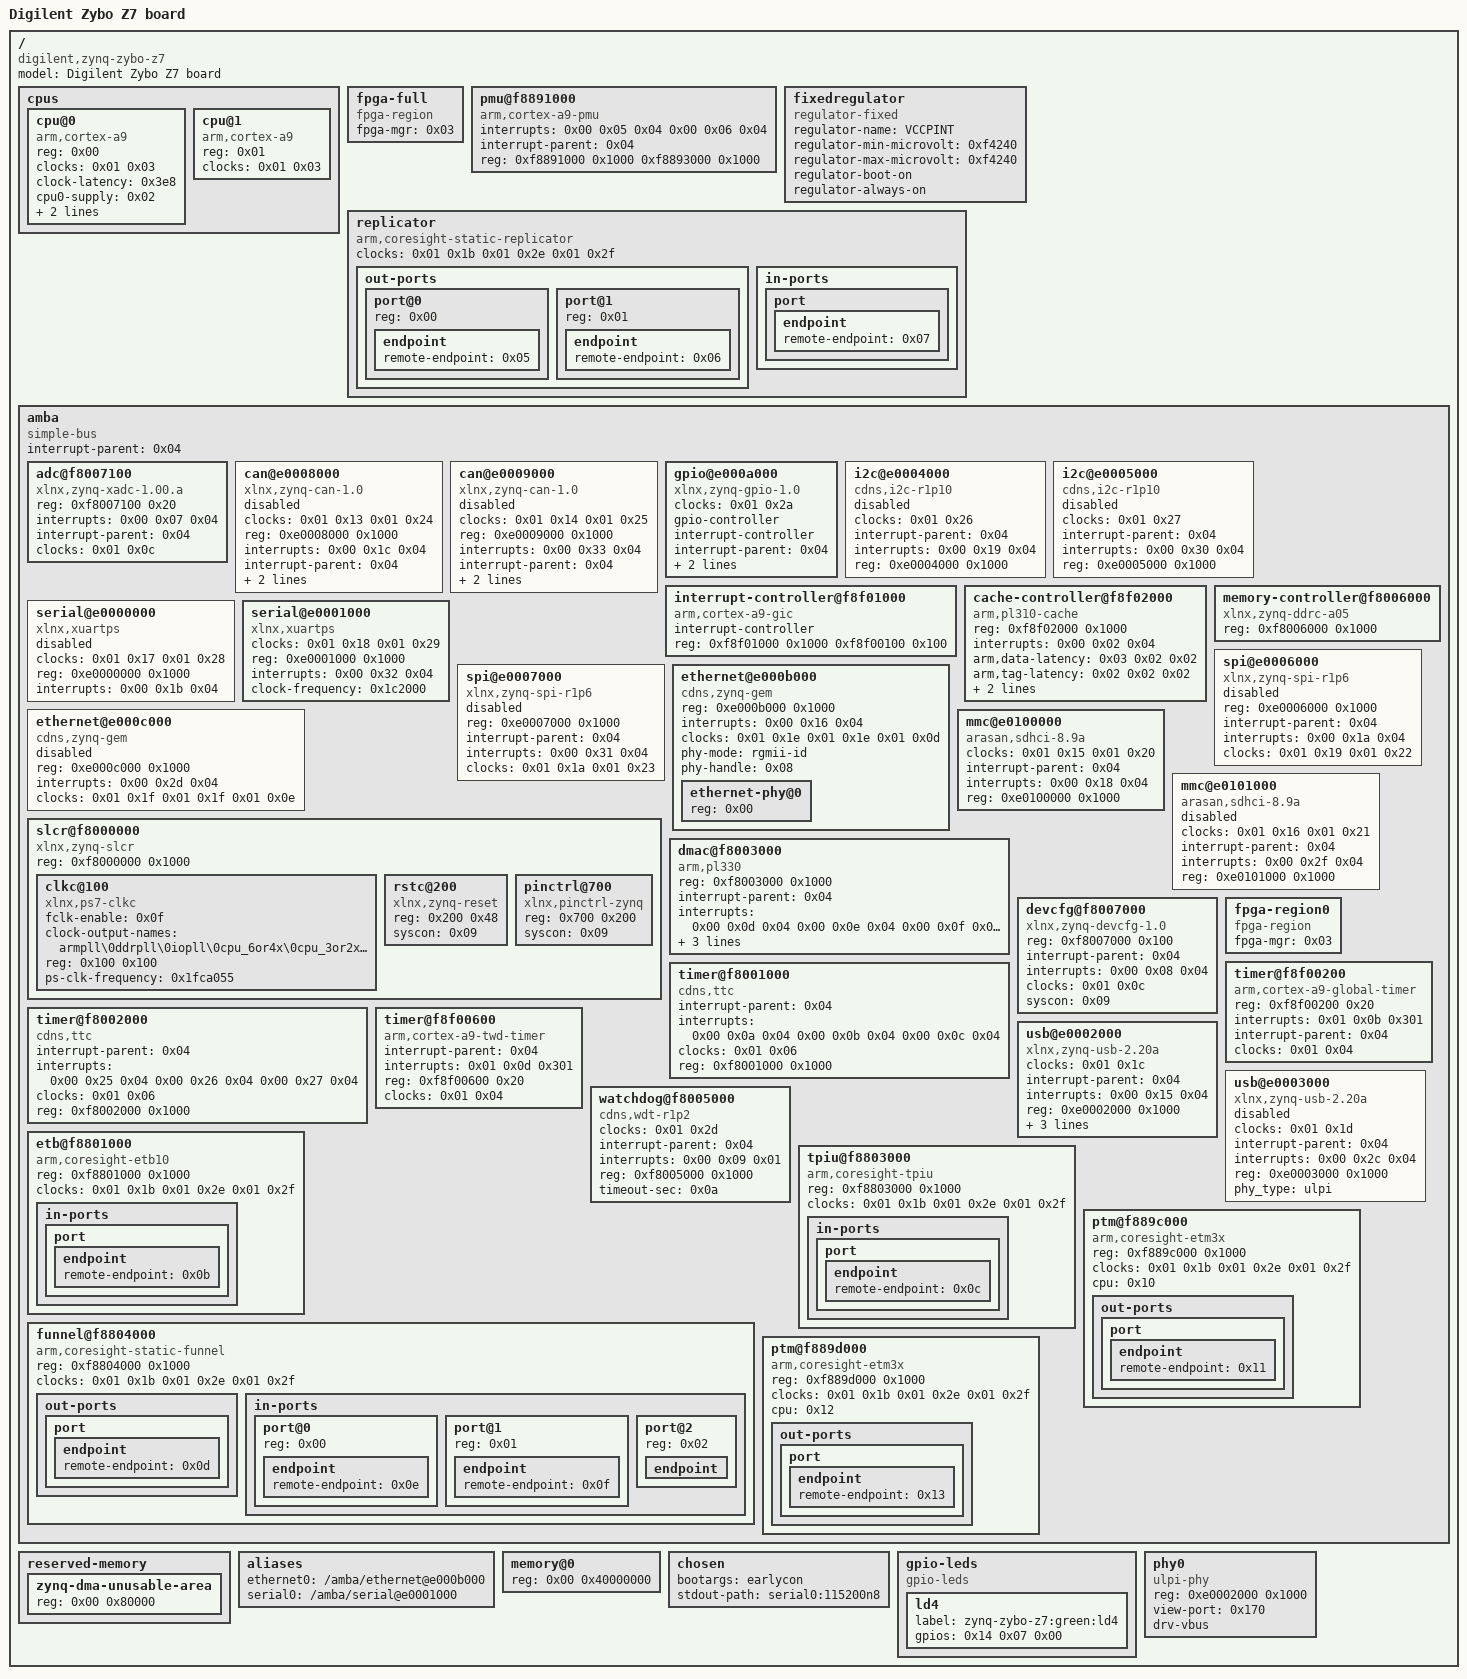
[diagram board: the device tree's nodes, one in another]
/dts-v1/;

/ {
	#address-cells = <0x01>;
	#size-cells = <0x01>;
	compatible = "digilent,zynq-zybo-z7\0xlnx,zynq-7000";
	model = "Digilent Zybo Z7 board";

	cpus {
		#address-cells = <0x01>;
		#size-cells = <0x00>;

		cpu@0 {
			compatible = "arm,cortex-a9";
			device_type = "cpu";
			reg = <0x00>;
			clocks = <0x01 0x03>;
			clock-latency = <0x3e8>;
			cpu0-supply = <0x02>;
			operating-points = <0xa2c2b 0xf4240 0x51616 0xf4240>;
			phandle = <0x10>;
		};

		cpu@1 {
			compatible = "arm,cortex-a9";
			device_type = "cpu";
			reg = <0x01>;
			clocks = <0x01 0x03>;
			phandle = <0x12>;
		};
	};

	fpga-full {
		compatible = "fpga-region";
		fpga-mgr = <0x03>;
		#address-cells = <0x01>;
		#size-cells = <0x01>;
		ranges;
		phandle = <0x15>;
	};

	pmu@f8891000 {
		compatible = "arm,cortex-a9-pmu";
		interrupts = <0x00 0x05 0x04 0x00 0x06 0x04>;
		interrupt-parent = <0x04>;
		reg = <0xf8891000 0x1000 0xf8893000 0x1000>;
	};

	fixedregulator {
		compatible = "regulator-fixed";
		regulator-name = "VCCPINT";
		regulator-min-microvolt = <0xf4240>;
		regulator-max-microvolt = <0xf4240>;
		regulator-boot-on;
		regulator-always-on;
		phandle = <0x02>;
	};

	replicator {
		compatible = "arm,coresight-static-replicator";
		clocks = <0x01 0x1b 0x01 0x2e 0x01 0x2f>;
		clock-names = "apb_pclk\0dbg_trc\0dbg_apb";

		out-ports {
			#address-cells = <0x01>;
			#size-cells = <0x00>;

			port@0 {
				reg = <0x00>;

				endpoint {
					remote-endpoint = <0x05>;
					phandle = <0x0c>;
				};
			};

			port@1 {
				reg = <0x01>;

				endpoint {
					remote-endpoint = <0x06>;
					phandle = <0x0b>;
				};
			};
		};

		in-ports {

			port {

				endpoint {
					remote-endpoint = <0x07>;
					phandle = <0x0d>;
				};
			};
		};
	};

	amba {
		compatible = "simple-bus";
		#address-cells = <0x01>;
		#size-cells = <0x01>;
		interrupt-parent = <0x04>;
		ranges;
		phandle = <0x16>;

		adc@f8007100 {
			compatible = "xlnx,zynq-xadc-1.00.a";
			reg = <0xf8007100 0x20>;
			interrupts = <0x00 0x07 0x04>;
			interrupt-parent = <0x04>;
			clocks = <0x01 0x0c>;
			phandle = <0x17>;
		};

		can@e0008000 {
			compatible = "xlnx,zynq-can-1.0";
			status = "disabled";
			clocks = <0x01 0x13 0x01 0x24>;
			clock-names = "can_clk\0pclk";
			reg = <0xe0008000 0x1000>;
			interrupts = <0x00 0x1c 0x04>;
			interrupt-parent = <0x04>;
			tx-fifo-depth = <0x40>;
			rx-fifo-depth = <0x40>;
			phandle = <0x18>;
		};

		can@e0009000 {
			compatible = "xlnx,zynq-can-1.0";
			status = "disabled";
			clocks = <0x01 0x14 0x01 0x25>;
			clock-names = "can_clk\0pclk";
			reg = <0xe0009000 0x1000>;
			interrupts = <0x00 0x33 0x04>;
			interrupt-parent = <0x04>;
			tx-fifo-depth = <0x40>;
			rx-fifo-depth = <0x40>;
			phandle = <0x19>;
		};

		gpio@e000a000 {
			compatible = "xlnx,zynq-gpio-1.0";
			#gpio-cells = <0x02>;
			clocks = <0x01 0x2a>;
			gpio-controller;
			interrupt-controller;
			#interrupt-cells = <0x02>;
			interrupt-parent = <0x04>;
			interrupts = <0x00 0x14 0x04>;
			reg = <0xe000a000 0x1000>;
			phandle = <0x14>;
		};

		i2c@e0004000 {
			compatible = "cdns,i2c-r1p10";
			status = "disabled";
			clocks = <0x01 0x26>;
			interrupt-parent = <0x04>;
			interrupts = <0x00 0x19 0x04>;
			reg = <0xe0004000 0x1000>;
			#address-cells = <0x01>;
			#size-cells = <0x00>;
			phandle = <0x1a>;
		};

		i2c@e0005000 {
			compatible = "cdns,i2c-r1p10";
			status = "disabled";
			clocks = <0x01 0x27>;
			interrupt-parent = <0x04>;
			interrupts = <0x00 0x30 0x04>;
			reg = <0xe0005000 0x1000>;
			#address-cells = <0x01>;
			#size-cells = <0x00>;
			phandle = <0x1b>;
		};

		interrupt-controller@f8f01000 {
			compatible = "arm,cortex-a9-gic";
			#interrupt-cells = <0x03>;
			interrupt-controller;
			reg = <0xf8f01000 0x1000 0xf8f00100 0x100>;
			phandle = <0x04>;
		};

		cache-controller@f8f02000 {
			compatible = "arm,pl310-cache";
			reg = <0xf8f02000 0x1000>;
			interrupts = <0x00 0x02 0x04>;
			arm,data-latency = <0x03 0x02 0x02>;
			arm,tag-latency = <0x02 0x02 0x02>;
			cache-unified;
			cache-level = <0x02>;
			phandle = <0x1c>;
		};

		memory-controller@f8006000 {
			compatible = "xlnx,zynq-ddrc-a05";
			reg = <0xf8006000 0x1000>;
			phandle = <0x1d>;
		};

		serial@e0000000 {
			compatible = "xlnx,xuartps\0cdns,uart-r1p8";
			status = "disabled";
			clocks = <0x01 0x17 0x01 0x28>;
			clock-names = "uart_clk\0pclk";
			reg = <0xe0000000 0x1000>;
			interrupts = <0x00 0x1b 0x04>;
			phandle = <0x1e>;
		};

		serial@e0001000 {
			compatible = "xlnx,xuartps\0cdns,uart-r1p8";
			status = "okay";
			clocks = <0x01 0x18 0x01 0x29>;
			clock-names = "uart_clk\0pclk";
			reg = <0xe0001000 0x1000>;
			interrupts = <0x00 0x32 0x04>;
			clock-frequency = <0x1c2000>;
			phandle = <0x1f>;
		};

		spi@e0006000 {
			compatible = "xlnx,zynq-spi-r1p6";
			reg = <0xe0006000 0x1000>;
			status = "disabled";
			interrupt-parent = <0x04>;
			interrupts = <0x00 0x1a 0x04>;
			clocks = <0x01 0x19 0x01 0x22>;
			clock-names = "ref_clk\0pclk";
			#address-cells = <0x01>;
			#size-cells = <0x00>;
			phandle = <0x20>;
		};

		spi@e0007000 {
			compatible = "xlnx,zynq-spi-r1p6";
			reg = <0xe0007000 0x1000>;
			status = "disabled";
			interrupt-parent = <0x04>;
			interrupts = <0x00 0x31 0x04>;
			clocks = <0x01 0x1a 0x01 0x23>;
			clock-names = "ref_clk\0pclk";
			#address-cells = <0x01>;
			#size-cells = <0x00>;
			phandle = <0x21>;
		};

		ethernet@e000b000 {
			compatible = "cdns,zynq-gem\0cdns,gem";
			reg = <0xe000b000 0x1000>;
			status = "okay";
			interrupts = <0x00 0x16 0x04>;
			clocks = <0x01 0x1e 0x01 0x1e 0x01 0x0d>;
			clock-names = "pclk\0hclk\0tx_clk";
			#address-cells = <0x01>;
			#size-cells = <0x00>;
			phy-mode = "rgmii-id";
			phy-handle = <0x08>;
			phandle = <0x22>;

			ethernet-phy@0 {
				reg = <0x00>;
				device_type = "ethernet-phy";
				phandle = <0x08>;
			};
		};

		ethernet@e000c000 {
			compatible = "cdns,zynq-gem\0cdns,gem";
			reg = <0xe000c000 0x1000>;
			status = "disabled";
			interrupts = <0x00 0x2d 0x04>;
			clocks = <0x01 0x1f 0x01 0x1f 0x01 0x0e>;
			clock-names = "pclk\0hclk\0tx_clk";
			#address-cells = <0x01>;
			#size-cells = <0x00>;
			phandle = <0x23>;
		};

		mmc@e0100000 {
			compatible = "arasan,sdhci-8.9a";
			status = "okay";
			clock-names = "clk_xin\0clk_ahb";
			clocks = <0x01 0x15 0x01 0x20>;
			interrupt-parent = <0x04>;
			interrupts = <0x00 0x18 0x04>;
			reg = <0xe0100000 0x1000>;
			phandle = <0x24>;
		};

		mmc@e0101000 {
			compatible = "arasan,sdhci-8.9a";
			status = "disabled";
			clock-names = "clk_xin\0clk_ahb";
			clocks = <0x01 0x16 0x01 0x21>;
			interrupt-parent = <0x04>;
			interrupts = <0x00 0x2f 0x04>;
			reg = <0xe0101000 0x1000>;
			phandle = <0x25>;
		};

		slcr@f8000000 {
			#address-cells = <0x01>;
			#size-cells = <0x01>;
			compatible = "xlnx,zynq-slcr\0syscon\0simple-mfd";
			reg = <0xf8000000 0x1000>;
			ranges;
			phandle = <0x09>;

			clkc@100 {
				#clock-cells = <0x01>;
				compatible = "xlnx,ps7-clkc";
				fclk-enable = <0x0f>;
				clock-output-names = "armpll\0ddrpll\0iopll\0cpu_6or4x\0cpu_3or2x\0cpu_2x\0cpu_1x\0ddr2x\0ddr3x\0dci\0lqspi\0smc\0pcap\0gem0\0gem1\0fclk0\0fclk1\0fclk2\0fclk3\0can0\0can1\0sdio0\0sdio1\0uart0\0uart1\0spi0\0spi1\0dma\0usb0_aper\0usb1_aper\0gem0_aper\0gem1_aper\0sdio0_aper\0sdio1_aper\0spi0_aper\0spi1_aper\0can0_aper\0can1_aper\0i2c0_aper\0i2c1_aper\0uart0_aper\0uart1_aper\0gpio_aper\0lqspi_aper\0smc_aper\0swdt\0dbg_trc\0dbg_apb";
				reg = <0x100 0x100>;
				ps-clk-frequency = <0x1fca055>;
				phandle = <0x01>;
			};

			rstc@200 {
				compatible = "xlnx,zynq-reset";
				reg = <0x200 0x48>;
				#reset-cells = <0x01>;
				syscon = <0x09>;
				phandle = <0x26>;
			};

			pinctrl@700 {
				compatible = "xlnx,pinctrl-zynq";
				reg = <0x700 0x200>;
				syscon = <0x09>;
				phandle = <0x27>;
			};
		};

		dmac@f8003000 {
			compatible = "arm,pl330\0arm,primecell";
			reg = <0xf8003000 0x1000>;
			interrupt-parent = <0x04>;
			interrupt-names = "abort\0dma0\0dma1\0dma2\0dma3\0dma4\0dma5\0dma6\0dma7";
			interrupts = <0x00 0x0d 0x04 0x00 0x0e 0x04 0x00 0x0f 0x04 0x00 0x10 0x04 0x00 0x11 0x04 0x00 0x28 0x04 0x00 0x29 0x04 0x00 0x2a 0x04 0x00 0x2b 0x04>;
			#dma-cells = <0x01>;
			#dma-channels = <0x08>;
			#dma-requests = <0x04>;
			clocks = <0x01 0x1b>;
			clock-names = "apb_pclk";
			phandle = <0x28>;
		};

		devcfg@f8007000 {
			compatible = "xlnx,zynq-devcfg-1.0";
			reg = <0xf8007000 0x100>;
			interrupt-parent = <0x04>;
			interrupts = <0x00 0x08 0x04>;
			clocks = <0x01 0x0c>;
			clock-names = "ref_clk";
			syscon = <0x09>;
			phandle = <0x03>;
		};

		fpga-region0 {
			compatible = "fpga-region";
			fpga-mgr = <0x03>;
			#address-cells = <0x01>;
			#size-cells = <0x01>;
			ranges;
			phandle = <0x29>;
		};

		timer@f8f00200 {
			compatible = "arm,cortex-a9-global-timer";
			reg = <0xf8f00200 0x20>;
			interrupts = <0x01 0x0b 0x301>;
			interrupt-parent = <0x04>;
			clocks = <0x01 0x04>;
			phandle = <0x2a>;
		};

		timer@f8001000 {
			interrupt-parent = <0x04>;
			interrupts = <0x00 0x0a 0x04 0x00 0x0b 0x04 0x00 0x0c 0x04>;
			compatible = "cdns,ttc";
			clocks = <0x01 0x06>;
			reg = <0xf8001000 0x1000>;
			phandle = <0x2b>;
		};

		timer@f8002000 {
			interrupt-parent = <0x04>;
			interrupts = <0x00 0x25 0x04 0x00 0x26 0x04 0x00 0x27 0x04>;
			compatible = "cdns,ttc";
			clocks = <0x01 0x06>;
			reg = <0xf8002000 0x1000>;
			phandle = <0x2c>;
		};

		timer@f8f00600 {
			interrupt-parent = <0x04>;
			interrupts = <0x01 0x0d 0x301>;
			compatible = "arm,cortex-a9-twd-timer";
			reg = <0xf8f00600 0x20>;
			clocks = <0x01 0x04>;
			phandle = <0x2d>;
		};

		usb@e0002000 {
			compatible = "xlnx,zynq-usb-2.20a\0chipidea,usb2";
			status = "okay";
			clocks = <0x01 0x1c>;
			interrupt-parent = <0x04>;
			interrupts = <0x00 0x15 0x04>;
			reg = <0xe0002000 0x1000>;
			phy_type = "ulpi";
			dr_mode = "host";
			usb-phy = <0x0a>;
			phandle = <0x2e>;
		};

		usb@e0003000 {
			compatible = "xlnx,zynq-usb-2.20a\0chipidea,usb2";
			status = "disabled";
			clocks = <0x01 0x1d>;
			interrupt-parent = <0x04>;
			interrupts = <0x00 0x2c 0x04>;
			reg = <0xe0003000 0x1000>;
			phy_type = "ulpi";
			phandle = <0x2f>;
		};

		watchdog@f8005000 {
			clocks = <0x01 0x2d>;
			compatible = "cdns,wdt-r1p2";
			interrupt-parent = <0x04>;
			interrupts = <0x00 0x09 0x01>;
			reg = <0xf8005000 0x1000>;
			timeout-sec = <0x0a>;
			phandle = <0x30>;
		};

		etb@f8801000 {
			compatible = "arm,coresight-etb10\0arm,primecell";
			reg = <0xf8801000 0x1000>;
			clocks = <0x01 0x1b 0x01 0x2e 0x01 0x2f>;
			clock-names = "apb_pclk\0dbg_trc\0dbg_apb";

			in-ports {

				port {

					endpoint {
						remote-endpoint = <0x0b>;
						phandle = <0x06>;
					};
				};
			};
		};

		tpiu@f8803000 {
			compatible = "arm,coresight-tpiu\0arm,primecell";
			reg = <0xf8803000 0x1000>;
			clocks = <0x01 0x1b 0x01 0x2e 0x01 0x2f>;
			clock-names = "apb_pclk\0dbg_trc\0dbg_apb";

			in-ports {

				port {

					endpoint {
						remote-endpoint = <0x0c>;
						phandle = <0x05>;
					};
				};
			};
		};

		funnel@f8804000 {
			compatible = "arm,coresight-static-funnel\0arm,primecell";
			reg = <0xf8804000 0x1000>;
			clocks = <0x01 0x1b 0x01 0x2e 0x01 0x2f>;
			clock-names = "apb_pclk\0dbg_trc\0dbg_apb";

			out-ports {

				port {

					endpoint {
						remote-endpoint = <0x0d>;
						phandle = <0x07>;
					};
				};
			};

			in-ports {
				#address-cells = <0x01>;
				#size-cells = <0x00>;

				port@0 {
					reg = <0x00>;

					endpoint {
						remote-endpoint = <0x0e>;
						phandle = <0x11>;
					};
				};

				port@1 {
					reg = <0x01>;

					endpoint {
						remote-endpoint = <0x0f>;
						phandle = <0x13>;
					};
				};

				port@2 {
					reg = <0x02>;

					endpoint {
						phandle = <0x31>;
					};
				};
			};
		};

		ptm@f889c000 {
			compatible = "arm,coresight-etm3x\0arm,primecell";
			reg = <0xf889c000 0x1000>;
			clocks = <0x01 0x1b 0x01 0x2e 0x01 0x2f>;
			clock-names = "apb_pclk\0dbg_trc\0dbg_apb";
			cpu = <0x10>;

			out-ports {

				port {

					endpoint {
						remote-endpoint = <0x11>;
						phandle = <0x0e>;
					};
				};
			};
		};

		ptm@f889d000 {
			compatible = "arm,coresight-etm3x\0arm,primecell";
			reg = <0xf889d000 0x1000>;
			clocks = <0x01 0x1b 0x01 0x2e 0x01 0x2f>;
			clock-names = "apb_pclk\0dbg_trc\0dbg_apb";
			cpu = <0x12>;

			out-ports {

				port {

					endpoint {
						remote-endpoint = <0x13>;
						phandle = <0x0f>;
					};
				};
			};
		};
	};

	reserved-memory {
		#address-cells = <0x01>;
		#size-cells = <0x01>;
		ranges;

		zynq-dma-unusable-area {
			reg = <0x00 0x80000>;
		};
	};

	aliases {
		ethernet0 = "/amba/ethernet@e000b000";
		serial0 = "/amba/serial@e0001000";
	};

	memory@0 {
		device_type = "memory";
		reg = <0x00 0x40000000>;
	};

	chosen {
		bootargs = "earlycon";
		stdout-path = "serial0:115200n8";
	};

	gpio-leds {
		compatible = "gpio-leds";

		ld4 {
			label = "zynq-zybo-z7:green:ld4";
			gpios = <0x14 0x07 0x00>;
		};
	};

	phy0 {
		compatible = "ulpi-phy";
		#phy-cells = <0x00>;
		reg = <0xe0002000 0x1000>;
		view-port = <0x170>;
		drv-vbus;
		phandle = <0x0a>;
	};

	__symbols__ {
		cpu0 = "/cpus/cpu@0";
		cpu1 = "/cpus/cpu@1";
		fpga_full = "/fpga-full";
		regulator_vccpint = "/fixedregulator";
		replicator_out_port0 = "/replicator/out-ports/port@0/endpoint";
		replicator_out_port1 = "/replicator/out-ports/port@1/endpoint";
		replicator_in_port0 = "/replicator/in-ports/port/endpoint";
		amba = "/amba";
		adc = "/amba/adc@f8007100";
		can0 = "/amba/can@e0008000";
		can1 = "/amba/can@e0009000";
		gpio0 = "/amba/gpio@e000a000";
		i2c0 = "/amba/i2c@e0004000";
		i2c1 = "/amba/i2c@e0005000";
		intc = "/amba/interrupt-controller@f8f01000";
		L2 = "/amba/cache-controller@f8f02000";
		mc = "/amba/memory-controller@f8006000";
		uart0 = "/amba/serial@e0000000";
		uart1 = "/amba/serial@e0001000";
		spi0 = "/amba/spi@e0006000";
		spi1 = "/amba/spi@e0007000";
		gem0 = "/amba/ethernet@e000b000";
		ethernet_phy = "/amba/ethernet@e000b000/ethernet-phy@0";
		gem1 = "/amba/ethernet@e000c000";
		sdhci0 = "/amba/mmc@e0100000";
		sdhci1 = "/amba/mmc@e0101000";
		slcr = "/amba/slcr@f8000000";
		clkc = "/amba/slcr@f8000000/clkc@100";
		rstc = "/amba/slcr@f8000000/rstc@200";
		pinctrl0 = "/amba/slcr@f8000000/pinctrl@700";
		dmac_s = "/amba/dmac@f8003000";
		devcfg = "/amba/devcfg@f8007000";
		fpga_region0 = "/amba/fpga-region0";
		global_timer = "/amba/timer@f8f00200";
		ttc0 = "/amba/timer@f8001000";
		ttc1 = "/amba/timer@f8002000";
		scutimer = "/amba/timer@f8f00600";
		usb0 = "/amba/usb@e0002000";
		usb1 = "/amba/usb@e0003000";
		watchdog0 = "/amba/watchdog@f8005000";
		etb_in_port = "/amba/etb@f8801000/in-ports/port/endpoint";
		tpiu_in_port = "/amba/tpiu@f8803000/in-ports/port/endpoint";
		funnel_out_port = "/amba/funnel@f8804000/out-ports/port/endpoint";
		funnel0_in_port0 = "/amba/funnel@f8804000/in-ports/port@0/endpoint";
		funnel0_in_port1 = "/amba/funnel@f8804000/in-ports/port@1/endpoint";
		funnel0_in_port2 = "/amba/funnel@f8804000/in-ports/port@2/endpoint";
		ptm0_out_port = "/amba/ptm@f889c000/out-ports/port/endpoint";
		ptm1_out_port = "/amba/ptm@f889d000/out-ports/port/endpoint";
		usb_phy0 = "/phy0";
	};
};
